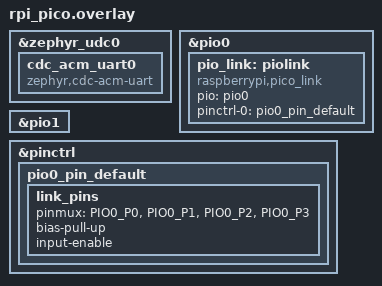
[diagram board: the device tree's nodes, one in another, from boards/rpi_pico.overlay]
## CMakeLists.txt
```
cmake_minimum_required(VERSION 3.20.0)

set(CMAKE_CXX_STANDARD 20)
set(CMAKE_CXX_STANDARD_REQUIRED ON)

# The following resolves the Zephyr location using the ZEPHYR_BASE environment variable.
# The `REQUIRED HINTS $ENV{ZEPHYR_BASE}` is optional in case you're not using `west zephyr-export`
# https://docs.zephyrproject.org/latest/develop/west/zephyr-cmds.html#installing-cmake-packages-west-zephyr-export

# Only set ZEPHYR_MODULES manually if modules are vendored locally.
# When building with west, modules are discovered automatically.
if(EXISTS "${CMAKE_SOURCE_DIR}/modules/hal/rpi_pico")
    set(ZEPHYR_MODULES "${CMAKE_SOURCE_DIR}/modules/hal/rpi_pico" "${CMAKE_SOURCE_DIR}/modules/hal/cmsis")
endif()

set(BOARD rpi_pico)

find_package(Zephyr REQUIRED HINTS "${CMAKE_SOURCE_DIR}/zephyr" $ENV{ZEPHYR_BASE})

project(
    EmptyApp
    VERSION 0.1
    DESCRIPTION "Empty Zephyr application."
    LANGUAGES C
)

# The target "app" is defined in Zephyr's CMake package and is the default target for Zephyr apps.
target_sources(
    app
    PRIVATE
    src/main.cpp
    src/hardware.cpp
    src/persist.cpp
)

set_compiler_property(PROPERTY diagnostic -fdiagnostics-color=never)


add_subdirectory(src/layers)
add_subdirectory(src/payloads)
add_subdirectory(src/sections)
add_subdirectory(src/module)
```

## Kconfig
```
mainmenu "GBLink Device Settings"
source "Kconfig.zephyr"

menu "Application Options"
    config SECTIONS_USE_MASTER_MODE
    bool "Use master mode to connect"
    default y
    help
        Use master mode to connect. 
        Disbale for slave mode to help debug slave setting
        WARNING for future Nils: This will probably not work since Game saves player under player ID which will swap if
        in next section device will switch to master. Why it works in "disconnect" is unkown, but probably due to slightly
        different code paths. To confirm see "DoesLinkPlayerCountMatchSaved" and change accordingly 

    config GB_LINK_MODE_ENABLED
    bool "Enable Game Boy link mode"
    default y
    help
        Enable support for Game Boy link communication.
        This adds the GB SPI passthrough and printer modes.

    config GB_LINK_DRIVE_SD_LOW
    bool "Drive SD pin LOW in GB link mode (generic GBC cable GBA support)"
    default n
    depends on GB_LINK_MODE_ENABLED
    help
        Drive the SD pin (pin 4 of the link connector) LOW whenever GB link
        mode is active.

        OEM GBC link cables leave pin 4 unconnected, so this has no effect
        on them. Generic GBC cables wire all 6 pins through, including pin 4,
        which means the SD signal actually reaches the GBA.

        The GBA reads SIOCNT bit 3 (SD state) to detect whether an external
        clock master is present. With SD floating HIGH (the default when this
        option is off) the GBA may not recognise the adapter as the master,
        causing GBA-mode transfers to fail. Driving SD LOW tells the GBA that
        an external device is driving the clock, which is the correct state
        when the adapter is acting as SPI master.

        Enable this option when using a generic GBC cable to connect to a GBA
        (e.g. for Gen 3 trading or multiboot). Safe to leave enabled even with
        OEM cables or original GB/GBC hardware — those devices either ignore
        the SD pin or treat SD LOW as a valid "external master" signal.

    config GBC_CABLE_ON_GBA
    bool "Use generic GBC cable for GBA mode (SD on GP4)"
    default n
    help
        Enable when using a generic GBC link cable to connect to a GBA.
        Generic GBC cables wire all 6 pins through; on this PCB that routes
        the SD signal to GP4 rather than the standard GP3. Without this
        option SD is read from GP3 (correct for OEM GBA cables).
endmenu
```

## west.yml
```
manifest:
  self:
    path: gblink-firmware

  remotes:
    - name: zephyrproject-rtos
      url-base: https://github.com/zephyrproject-rtos

  projects:
    - name: zephyr
      remote: zephyrproject-rtos
      revision: v4.4-branch
      import:
        name-allowlist:
          - cmsis
          - hal_rpi_pico
```

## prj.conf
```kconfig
CONFIG_GPIO=y
CONFIG_DMA=y
CONFIG_COUNTER=y
CONFIG_EVENTS=y

CONFIG_SPEED_OPTIMIZATIONS=n
CONFIG_DEBUG=y

CONFIG_STDOUT_CONSOLE=y
CONFIG_USB_DEVICE_STACK=y
CONFIG_USB_DEVICE_BOS=y
CONFIG_USB_COMPOSITE_DEVICE=y
CONFIG_USB_CDC_ACM=y
# Composite (vendor + CDC) needs more concurrent transfers than the defaults.
CONFIG_USB_MAX_NUM_TRANSFERS=8
CONFIG_USB_NUMOF_EP_WRITE_RETRIES=10
CONFIG_SERIAL=y
CONFIG_USB_DEVICE_PRODUCT="GBLink USB"
CONFIG_USB_DEVICE_PID=0x000A
CONFIG_UART_INTERRUPT_DRIVEN=y
CONFIG_UART_LINE_CTRL=y
CONFIG_RING_BUFFER=y
CONFIG_USB_DEVICE_INITIALIZE_AT_BOOT=n

CONFIG_CPP=y
CONFIG_STD_CPP20=y
CONFIG_NEWLIB_LIBC=y
CONFIG_NEWLIB_LIBC_NANO=y
CONFIG_REQUIRES_FULL_LIBCPP=y

CONFIG_TICKLESS_KERNEL=y

CONFIG_THREAD_MONITOR=y
CONFIG_THREAD_NAME=y
CONFIG_DEBUG_THREAD_INFO=y
CONFIG_ASSERT=y

CONFIG_PINCTRL=y

# Flash storage for persistent settings (the WebUSB landing-page toggle).
CONFIG_FLASH=y
CONFIG_FLASH_MAP=y
CONFIG_FLASH_PAGE_LAYOUT=y

CONFIG_SECTIONS_USE_MASTER_MODE=y
CONFIG_REBOOT=y
# Driving SD low is opt-in (off by default). For rare compatibility issues with some GBAs.
CONFIG_GB_LINK_DRIVE_SD_LOW=n
```

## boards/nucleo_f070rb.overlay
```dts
#include <zephyr/dt-bindings/pinctrl/stm32-pinctrl.h>

&dma1 { 
    status = "okay";
};

&usb {
    pinctrl-0 = <&usb_dm_pa11 &usb_dp_pa12>;
	pinctrl-names = "default";
    status = "okay";

    cdc_acm_uart0: cdc_acm_uart0 {
        compatible = "zephyr,cdc-acm-uart";
    };
};

&timers16 {
    status = "okay";
    st,prescaler = <0x0F>;
    counter {
        status = "okay";
    };
};

&timers17 {
    status = "okay";
    st,prescaler = <0>;
    counter {
        status = "okay";
    };
};
```

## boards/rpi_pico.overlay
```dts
#include <zephyr/dt-bindings/pinctrl/rpi-pico-rp2040-pinctrl.h>

&zephyr_udc0 {
    cdc_acm_uart0: cdc_acm_uart0 {
        compatible = "zephyr,cdc-acm-uart";
    };
};

&pio0 {
    status = "okay";

    pio_link: piolink {
        compatible = "raspberrypi,pico_link";
        status = "okay";
        pio = <&pio0>;
        pinctrl-0 = <&pio0_pin_default>;
        pinctrl-names = "default";
    };
};

&pio1 {
    status = "okay";
};

&pinctrl {
    pio0_pin_default: pio0_pin_default {
        link_pins {
            pinmux = <PIO0_P0>, <PIO0_P1>, <PIO0_P2>, <PIO0_P3>;
            bias-pull-up;
            input-enable;
        };
    };
};
```

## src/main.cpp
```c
#include <zephyr/kernel.h>

#include "control.hpp"

#include "./layers/packet/packetLayer.hpp"

#include "link_defines.h"

int main(void)
{
    Control g_control = Control();
    while (true)
    {
        g_control.executeMode();
    }
    

    return 0;
}
```

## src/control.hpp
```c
#include "layers/usbLayer.hpp"
#include "layers/serialLayer.hpp"
#include "layers/transport.hpp"
#include "layers/packet/packetLayer.hpp"
#include "module/link.hpp"
#include "module/emu.hpp"
#include "module/gb.hpp"
#include "module/advanceWars.hpp"
#include "module/eReader.hpp"
#include "sections/eReaderProtocolSection.hpp"
#include "linkStatus.hpp"
#include "layers/packet/packetCommands/commands.hpp"
#include "payloads/pokemon.hpp"
#include "module/moduleInterface.hpp"
#include "hardware.hpp"
#include "persist.hpp"
#include "firmware_version.hpp"

class Control
{
    enum class ControlCommand
    {
        SetMode = 0x00,
        Cancel = 0x01,
        EnterGBPrinter = 0x03,
        GetFirmwareInfo = 0x0F
    };

    enum class Mode
    {
        gbaTradeEmu = 0x00,
        gbaLink = 0x01,
        gbLink = 0x02,
        gbPrinter = 0x03,
        advanceWars = 0x04,
        gbaEreader = 0x05,
    };

    static constexpr uint8_t callSetModeId = 0x01;

public:
    Control()
    {
        Transport::registerCommandHandler(receiveCommandHandler, this);

        k_sem_init(&m_waitForModeSemaphore, 0, 1);

        // Persisted cable selection = boot default for the session override.
        cableDetection_setCableOverride(getCableSelection());
    }

    void executeMode()
    {
        k_sem_take(&m_waitForModeSemaphore, K_FOREVER);
        // Capture the requested mode; callSetMode always sets m_mode before
        // giving the semaphore (including when preempting a running mode), so we
        // must not clobber it below. The variant travels with the mode.
        const Mode mode = m_mode;
        const uint8_t modeVariant = m_modeVariant;
        sendLinkStatus(LinkStatus::DeviceReady);

        switch (mode)
        {
            case Mode::gbaTradeEmu:
            {
                applyLedForSlot(LED_SLOT_GBA);
                cableDetection_detectCableType();

                party::partyInit();
                Transport::registerDataHandler(party::usbReceivePkmFile, nullptr);

                EmuModule emuModule;
                m_currentModule = &emuModule;
                emuModule.execute();

                sendLinkStatus(LinkStatus::EmuTradeSessionFinished);
                break;
            }

            case Mode::gbaLink:
            {
                applyLedForSlot(LED_SLOT_GBA);
                cableDetection_detectCableType();

                Transport::registerDataHandler(usbLink_receiveHandler, nullptr);

                LinkModule linkModule;
                m_currentModule = &linkModule;
                linkModule.execute();

                sendLinkStatus(LinkStatus::LinkClosed);
                break;
            }

            case Mode::gbLink:
            {
                GBModule gbModule;
                m_currentModule = &gbModule;
                gbModule.execute();  // Sets blue LED internally

                sendLinkStatus(LinkStatus::GBSessionFinished);
                break;
            }

            case Mode::gbPrinter:
            {
                GBModule gbModule;
                m_currentModule = &gbModule;
                gbModule.executePrinterMode();  // Sets purple LED internally

                sendLinkStatus(LinkStatus::GBSessionFinished);
                break;
            }

            case Mode::advanceWars:
            {
                applyLedForSlot(LED_SLOT_ADVANCE_WARS);
                cableDetection_detectCableType();

                Transport::registerDataHandler(awProto_receiveHandler, nullptr);

                AdvanceWarsModule advanceWarsModule(
                    modeVariant == 2 ? awproto::GameVariant::aw2
                                     : awproto::GameVariant::aw1);
                m_currentModule = &advanceWarsModule;
                advanceWarsModule.execute();

                sendLinkStatus(LinkStatus::LinkClosed);
                break;
            }

            case Mode::gbaEreader:
            {
                applyLedForSlot(LED_SLOT_EREADER);
                cableDetection_detectCableType();

                Transport::registerDataHandler(erProto_receiveHandler, nullptr);

                const erproto::Profile profile =
                    modeVariant == 2 ? erproto::Profile::pokemonRuby :
                    modeVariant == 3 ? erproto::Profile::sma4JPN :
                    modeVariant == 4 ? erproto::Profile::pokemonRubyJPN :
                    modeVariant == 5 ? erproto::Profile::sma4EUR :
                    modeVariant == 6 ? erproto::Profile::sma4EURFra :
                    modeVariant == 7 ? erproto::Profile::sma4EURGer :
                    modeVariant == 8 ? erproto::Profile::sma4EUREsp :
                    modeVariant == 9 ? erproto::Profile::sma4EURIta
                                   : erproto::Profile::sma4;
                EReaderModule ereaderModule(profile);
                m_currentModule = &ereaderModule;
                ereaderModule.execute();

                sendLinkStatus(LinkStatus::LinkClosed);
                break;
            }
        }

        m_currentModule = nullptr;
        applyLedForSlot(LED_SLOT_IDLE); // green = connected, no active mode
    }

private:
    struct k_sem m_waitForModeSemaphore;
    Mode m_mode;
    uint8_t m_modeVariant = 0;

    IModule* m_currentModule = nullptr;

    bool canHandle(uint8_t command) { return (command & 0xF0) == 0x00; }

    // Hardware commands (0x40-0x4F) are device-level, handled regardless of active module
    bool isHardwareCommand(uint8_t command) { return (command & 0xF0) == 0x40; }

    enum class HardwareCommand : uint8_t
    {
        SetVoltage3V3 = 0x40,
        SetVoltage5V = 0x41,
        SetLEDColor = 0x42,
        RebootBootloader = 0x43,
        SetWebUsbLanding = 0x44,
        GetLedConfig = 0x45,
        SetModeLedColor = 0x46,
        ResetLedColors = 0x47,
        Reboot = 0x48,
        SetCableOverride = 0x49,
        GetCableType = 0x4a,
        SetCableSelection = 0x4b,
    };

    void receiveCommand(std::span<const uint8_t> data)
    {
        if (data.empty()) return;

        // Handle hardware commands first (device-level, always available)
        if (isHardwareCommand(data[0]))
        {
            return handleHardwareCommand(data);
        }

        if (m_currentModule != nullptr && m_currentModule->canHandle(data[0]))
        {
            return m_currentModule->receiveCommand(data);
        } 
        
        if (!canHandle(data[0])) return;
        switch (static_cast<ControlCommand>(data[0]))
        {
            // Optional third byte selects a game variant within the mode
            // (Advance Wars: 1 = AW1, 2 = AW2; e-reader: 1 = SMA4 US,
            // 2 = Pokemon RS US, 3 = SMA4 JPN, 4 = Pokemon RS JPN,
            // 5-9 = SMA4 EUR En/Fr/De/Es/It; defaults to the first variant
            // for older clients that send only [command, mode]).
            case ControlCommand::SetMode:
                if (data.size() < 2) return;
                return callSetMode(static_cast<Mode>(data[1]),
                                   data.size() >= 3 ? data[2] : 0);
            case ControlCommand::Cancel: return callCancel();
            case ControlCommand::EnterGBPrinter: return callSetMode(Mode::gbPrinter);
            case ControlCommand::GetFirmwareInfo: return callGetFirmwareInfo();
            default: return;
        }
    }

    void handleHardwareCommand(std::span<const uint8_t> data)
    {
        switch (static_cast<HardwareCommand>(data[0]))
        {
            case HardwareCommand::SetVoltage3V3:
                Hardware::getInstance().setVoltage3V3();
                break;
            case HardwareCommand::SetVoltage5V:
                Hardware::getInstance().setVoltage5V();
                break;
            case HardwareCommand::SetLEDColor:
                if (data.size() >= 5) {
                    Hardware::getInstance().setLED(data[1], data[2], data[3], data[4] != 0);
                }
                break;
            case HardwareCommand::RebootBootloader:
                // Resets into the USB bootloader; does not return.
                Hardware::getInstance().rebootToBootloader();
                break;
            case HardwareCommand::SetWebUsbLanding:
                // Persist the WebUSB landing-page toggle; applies on next reconnect.
                if (data.size() >= 2) {
                    setLandingPageEnabled(data[1] != 0);
                }
                break;
            case HardwareCommand::GetLedConfig:
                return callGetLedConfig();
            case HardwareCommand::SetModeLedColor:
                // [0x46, slot, r, g, b] — persist a mode's LED colour.
                if (data.size() >= 5) {
                    setLedColor(data[1], data[2], data[3], data[4]);
                }
                break;
            case HardwareCommand::ResetLedColors:
                // Restore all per-mode LED colours to the built-in defaults.
                resetLedColors();
                break;
            case HardwareCommand::Reboot:
                // Warm-reboot into the app so persisted settings apply now; no return.
                Hardware::getInstance().reboot();
                break;
            case HardwareCommand::SetCableOverride:
                if (data.size() >= 2) {
                    cableDetection_setCableOverride(data[1]);
                }
                break;
            case HardwareCommand::GetCableType:
            {
                // Report-only: the cable is sampled once at mode entry (a GBA
                // already in link mode drives SO low, which would poison a
                // re-sample); the override command changes the path instead.
                uint8_t resp[2] = { 0x4a, static_cast<uint8_t>(cableDetection_getDetectedCableType()) };
                Transport::sendData(std::span<const uint8_t>(resp, sizeof(resp)));
                break;
            }
            case HardwareCommand::SetCableSelection:
                // [0x4b, CABLE_*] — persist the cable selection and apply it now.
                if (data.size() >= 2 && data[1] <= CABLE_FORCE_GBC) {
                    setCableSelection(data[1]);
                    cableDetection_setCableOverride(data[1]);
                }
                break;
            default: break;
        }
    }

    void callGetLedConfig()
    {
        // [0x45, count, r0,g0,b0, ... r5,g5,b5]
        uint8_t info[2 + LED_SLOT_COUNT * 3];
        info[0] = static_cast<uint8_t>(HardwareCommand::GetLedConfig);
        info[1] = LED_SLOT_COUNT;
        for (uint8_t slot = 0; slot < LED_SLOT_COUNT; slot++) {
            getLedColor(slot, &info[2 + slot * 3]);
        }
        Transport::sendData(std::span<const uint8_t>(info, sizeof(info)));
    }

    //-////////////////////////////////////////////////////////////////////////////////////////////////////////-//
    // CALLS
    //-////////////////////////////////////////////////////////////////////////////////////////////////////////-//

    void callSetMode(Mode mode, uint8_t variant = 0)
    {
        m_mode = mode;
        m_modeVariant = variant;
        // If a mode is already running, cancel it so executeMode unblocks and
        // switches to the new mode (otherwise SetMode would queue behind a mode
        // that never exits). Same cancel path the web "cancel" command uses.
        if (m_currentModule != nullptr)
        {
            m_currentModule->cancel();
        }
        k_sem_give(&m_waitForModeSemaphore);
    }

    void callCancel()
    {
        if (m_currentModule != nullptr) m_currentModule->cancel();
    }

    void callGetFirmwareInfo()
    {
        const uint8_t info[] = {
            0x0F, // Echo back the command ID so web app knows this is a firmware info response
            fw::versionMajor,
            fw::versionMinor,
            fw::versionPatch,
            // Byte 4: WebUSB landing-page enabled (1) / disabled (0). Older web
            // apps simply ignore the extra byte.
            static_cast<uint8_t>(landingPageEnabled() ? 1 : 0),
            // Byte 5: persisted cable selection (CABLE_*).
            getCableSelection()
        };
        Transport::sendData(std::span<const uint8_t>(info, sizeof(info)));
    }

    //-////////////////////////////////////////////////////////////////////////////////////////////////////////-//

    static void receiveCommandHandler(std::span<const uint8_t> receivedData, void* userData)
    {
        Control* self = static_cast<Control*>(userData);
        self->receiveCommand(receivedData);
    }
};
```

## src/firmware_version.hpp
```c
#pragma once

#include <cstdint>

// Single source for the firmware version. It is reported over the
// protocol (GetFirmwareInfo) and folded into the USB bcdDevice (see usbLayer.cpp).
//
// Why bcdDevice tracks the version: Windows caches a device's MS OS / WinUSB
// driver binding keyed by VID/PID/bcdDevice. If bcdDevice never changes, a host
// that cached an older descriptor keeps the stale binding after a firmware
// update and will not re-read the corrected descriptors. Advancing bcdDevice on
// every release makes Windows treat it as a new device and re-enumerate cleanly.
namespace fw
{
    inline constexpr uint8_t versionMajor = 2;
    inline constexpr uint8_t versionMinor = 2;
    inline constexpr uint8_t versionPatch = 1;

    // Packed BCD nibbles 0x0<major><minor><patch>, e.g. 2.2.1 -> 0x0221.
    // Keep each field <= 9 to stay valid BCD.
    inline constexpr uint16_t bcdDevice =
        (static_cast<uint16_t>(versionMajor) << 8) |
        (static_cast<uint16_t>(versionMinor) << 4) |
        static_cast<uint16_t>(versionPatch);
}
```

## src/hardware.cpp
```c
#include "hardware.hpp"

#include <zephyr/kernel.h>
#include "hardware/pio.h"
#include "hardware/gpio.h"
#include "hardware/clocks.h"
#include "hardware/timer.h"

extern "C" {
#include <zephyr/drivers/misc/pio_rpi_pico/pio_rpi_pico.h>
}

// --- Pin Definitions ---
#define WS2812_PIN      16
#define VSWITCH_3V3_PIN 11
#define VSWITCH_5V_PIN  12

// --- WS2812 PIO Program (4 instructions) ---
// Ported from gb-link-firmware-reconfigurable/main.c
static const uint16_t ws2812_program_instructions[] = {
    0x6221, //  0: out    x, 1       side 0 [2]
    0x1123, //  1: jmp    !x, 3      side 1 [1]
    0x1400, //  2: jmp    0          side 1 [4]
    0xa442, //  3: nop               side 0 [4]
};

static const struct pio_program ws2812_program = {
    .instructions = ws2812_program_instructions,
    .length = 4,
    .origin = -1,
};

// WS2812 uses pio1 (independent from link SPI on pio0)
static PIO g_ws2812_pio = NULL;
static uint g_ws2812_sm = 0;
static bool g_ws2812_initialized = false;

// --- Hardware Singleton ---

Hardware& Hardware::getInstance()
{
    static Hardware instance;
    return instance;
}

Hardware::Hardware()
{
    // Initialize voltage switching GPIOs (raw Pico SDK, matching linkLayer_pio.c pattern)
    gpio_init(VSWITCH_3V3_PIN);
    gpio_init(VSWITCH_5V_PIN);
    gpio_set_dir(VSWITCH_3V3_PIN, GPIO_OUT);
    gpio_set_dir(VSWITCH_5V_PIN, GPIO_OUT);

    // Safe state: both HIGH first
    gpio_put(VSWITCH_3V3_PIN, 1);
    gpio_put(VSWITCH_5V_PIN, 1);
    busy_wait_us(100);

    // Default to 3.3V mode
    gpio_put(VSWITCH_3V3_PIN, 0);

    // Initialize WS2812 NeoPixel
    ws2812Init();

    // Set initial LED to red (disconnected state)
    ws2812Set(0x000500); // GRB format: G=0x00, R=0x05, B=0x00
}

void Hardware::ws2812Init()
{
    // Pico SDK defines 'pio1' as a macro (pio1_hw) which breaks DT_NODELABEL.
    // Temporarily undefine it so device tree lookup works.
    #undef pio1
    const struct device* dev = DEVICE_DT_GET(DT_NODELABEL(pio1));
    if (!device_is_ready(dev)) {
        return;
    }

    g_ws2812_pio = pio_rpi_pico_get_pio(dev);
    pio_rpi_pico_allocate_sm(dev, &g_ws2812_sm);

    uint offset = pio_add_program(g_ws2812_pio, &ws2812_program);

    // Configure state machine for WS2812 protocol
    pio_gpio_init(g_ws2812_pio, WS2812_PIN);
    pio_sm_set_consecutive_pindirs(g_ws2812_pio, g_ws2812_sm, WS2812_PIN, 1, true);

    pio_sm_config c = pio_get_default_sm_config();
    sm_config_set_sideset(&c, 1, false, false);
    sm_config_set_sideset_pins(&c, WS2812_PIN);
    sm_config_set_out_shift(&c, false, true, 24);
    sm_config_set_fifo_join(&c, PIO_FIFO_JOIN_TX);
    sm_config_set_wrap(&c, offset, offset + 3);
    sm_config_set_clkdiv(&c, clock_get_hz(clk_sys) / (800000.0f * 8.0f));

    pio_sm_init(g_ws2812_pio, g_ws2812_sm, offset, &c);
    pio_sm_set_enabled(g_ws2812_pio, g_ws2812_sm, true);

    g_ws2812_initialized = true;
}

void Hardware::ws2812Set(uint32_t grb)
{
    if (!g_ws2812_initialized) return;
    pio_sm_put_blocking(g_ws2812_pio, g_ws2812_sm, grb << 8u);
}

// --- Public API ---

void Hardware::setVoltage3V3()
{
    // Both HIGH first (safe off), then pull 3.3V LOW
    gpio_put(VSWITCH_3V3_PIN, 1);
    gpio_put(VSWITCH_5V_PIN, 1);
    busy_wait_us(100);
    gpio_put(VSWITCH_3V3_PIN, 0);
}

void Hardware::setVoltage5V()
{
    // Both HIGH first (safe off), then pull 5V LOW
    gpio_put(VSWITCH_3V3_PIN, 1);
    gpio_put(VSWITCH_5V_PIN, 1);
    busy_wait_us(100);
    gpio_put(VSWITCH_5V_PIN, 0);
}

void Hardware::setLED(uint8_t r, uint8_t g, uint8_t b, bool on)
{
    if (on) {
        // NeoPixel expects GRB format
        uint32_t grb = ((uint32_t)g << 16) | ((uint32_t)r << 8) | b;
        ws2812Set(grb);
    } else {
        ws2812Set(0x000000);
    }
}

// --- Boot-time Initialization ---
static int hardware_init()
{
    Hardware::getInstance();
    return 0;
}

SYS_INIT(hardware_init, APPLICATION, 0);
```

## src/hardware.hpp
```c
#pragma once

#include <cstdint>

class Hardware {
public:
    static Hardware& getInstance();

    Hardware(const Hardware&) = delete;
    Hardware& operator=(const Hardware&) = delete;
    Hardware(Hardware&&) = delete;
    Hardware& operator=(Hardware&&) = delete;

    void setVoltage3V3();
    void setVoltage5V();
    void setLED(uint8_t r, uint8_t g, uint8_t b, bool on);

private:
    Hardware();
    void ws2812Init();
    void ws2812Set(uint32_t grb);
};
```

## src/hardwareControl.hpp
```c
#include "layers/transport/transportLayer.hpp"
#include "module/link.hpp"
#include "module/emu.hpp"
#include "module/advanceWars.hpp"
#include "callbacks/commands.hpp"
#include "hardware.hpp"
#include "persist.hpp"
#include <cstdint>

#pragma once

// Hardware commands (0x40-0x4F) are device-level, handled regardless of active module

    enum class HardwareCommand : uint8_t
    {
        SetVoltage = 0x40,
        SetLEDColor = 0x42,
        RebootBootloader = 0x43,
        SetWebUsbLanding = 0x44,
        GetLedConfig = 0x45,
        SetModeLedColor = 0x46,
        ResetLedColors = 0x47,
        Reboot = 0x48,
    };

class HardwareControl 
{
public:
    bool canHandle(uint8_t command) { return (command & 0xF0) == 0x40; }
    
    void handleCall(Call& call)
    {
        switch (static_cast<HardwareCommand>(call.fid))
        {
            case HardwareCommand::SetVoltage: return callSetVoltage(call);
            case HardwareCommand::SetLEDColor: return callSetLedColor(call);
            case HardwareCommand::RebootBootloader: return callReboot(call);
            case HardwareCommand::GetLedConfig: return callGetLedConfig(call);
            case HardwareCommand::SetModeLedColor: return callSetModeLedColor(call);
            case HardwareCommand::SetWebUsbLanding: return callSetWebUsbLanding(call);
            case HardwareCommand::ResetLedColors: return callResetColors(call);
            default: break;
        }
    }

private:
    void callGetLedConfig(Call& call)
    {
        // [0x45, count, r0,g0,b0, ... r4,g4,b4]
        uint8_t info[2 + LED_SLOT_COUNT * 3];
        info[0] = static_cast<uint8_t>(HardwareCommand::GetLedConfig);
        info[1] = LED_SLOT_COUNT;
        for (uint8_t slot = 0; slot < LED_SLOT_COUNT; slot++) {
            getLedColor(slot, &info[2 + slot * 3]);
        }
    }

    void callSetVoltage(Call& call)
    {
        switch(call.params()[0])
        {
            case 0x00: Hardware::getInstance().setVoltage3V3(); break;
            case 0x01: Hardware::getInstance().setVoltage5V(); break;
        };
    }

    void callSetLedColor(Call& call)
    {
        if (call.params().size() >= 4) 
        {
            Hardware::getInstance().setLED(
                call.params()[0], 
                call.params()[1], 
                call.params()[2], 
                call.params()[3] != 0
            );
        }
        break;
    }

    void callReboot(Call& call)
    {
        switch(call.params()[0])
        {
            case 0x00: Hardware::getInstance().rebootToBootloader(); break;
            case 0x01: Hardware::getInstance().reboot(); break;
        }
    }

    void callSetModeLedColor(Call& call)
    {
        if (call.params().size() >= 4) 
        {
            Hardware::getInstance().setLedColor(
                call.params()[0], 
                call.params()[1], 
                call.params()[2], 
                call.params()[3] != 0
            );
        }
        break;
    }

    void callSetWebUsbLanding(Call& call)
    {
        if (call.params().size() >= 1) 
        {
            setLandingPageEnabled(data[0] != 0);
        }
    }

    void callResetColors(Call& call)
    {
        resetLedColors();
    }
};
```

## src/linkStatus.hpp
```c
#include <zephyr/kernel.h>
#include "./layers/transport/transport.hpp"

#pragma once

enum class LinkStatus : uint16_t
{
    GameboyConnected = 0xFF00,
    GameboyDisconnected = 0xFF01,

    AwaitMode = 0xFF02,
    HandshakeReceived = 0xFF03,
    HandshakeFinished = 0xFF04,

    LinkConnected = 0xFF05,
    LinkReconnecting = 0xFF06,
    LinkClosed = 0xFF07,

    DeviceReady = 0xFF08,
    EmuTradeSessionFinished = 0xFF09,

    GBModeActive = 0xFF0A,
    GBPrinterModeActive = 0xFF0B,
    GBSessionFinished = 0xFF0C,

    StatusDebug = 0xFFFF
};

inline bool sendLinkStatus(LinkStatus status)
{
    return Transport::sendStatus(std::span<const uint8_t, 2>(reinterpret_cast<const uint8_t*>(&status), 2));
}
```

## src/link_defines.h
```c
#define LINKCMD_BLENDER_STOP            0x1111
#define LINKCMD_SEND_LINK_TYPE          0x2222
#define LINKCMD_BLENDER_SCORE_MISS      0x2345
#define LINKCMD_READY_EXIT_STANDBY      0x2FFE
#define LINKCMD_SEND_PACKET             0x2FFF
#define LINKCMD_BLENDER_SEND_KEYS       0x4444
#define LINKCMD_BLENDER_SCORE_BEST      0x4523
#define LINKCMD_BLENDER_SCORE_GOOD      0x5432
#define LINKCMD_DUMMY_1                 0x5555
#define LINKCMD_DUMMY_2                 0x5566
#define LINKCMD_READY_CLOSE_LINK        0x5FFF
#define LINKCMD_SEND_EMPTY              0x6666
#define LINKCMD_SEND_0xEE               0x7777
#define LINKCMD_BLENDER_PLAY_AGAIN      0x7779
#define LINKCMD_COUNTDOWN               0x7FFF
#define LINKCMD_CONT_BLOCK              0x8888
#define LINKCMD_BLENDER_NO_BERRIES      0x9999
#define LINKCMD_BLENDER_NO_PBLOCK_SPACE 0xAAAA
#define LINKCMD_SEND_ITEM               0xAAAB
#define LINKCMD_READY_TO_TRADE          0xAABB
#define LINKCMD_READY_FINISH_TRADE      0xABCD
#define LINKCMD_INIT_BLOCK              0xBBBB
#define LINKCMD_READY_CANCEL_TRADE      0xBBCC
#define LINKCMD_SEND_HELD_KEYS          0xCAFE
#define LINKCMD_SEND_BLOCK_REQ          0xCCCC
#define LINKCMD_START_TRADE             0xCCDD
#define LINKCMD_CONFIRM_FINISH_TRADE    0xDCBA
#define LINKCMD_SET_MONS_TO_TRADE       0xDDDD
#define LINKCMD_PLAYER_CANCEL_TRADE     0xDDEE
#define LINKCMD_REQUEST_CANCEL          0xEEAA
#define LINKCMD_BOTH_CANCEL_TRADE       0xEEBB
#define LINKCMD_PARTNER_CANCEL_TRADE    0xEECC
#define LINKCMD_NONE                    0xEFFF

#define LINKCMD_EMPTY                   0x0000

#define LINKTYPE_TRADE               0x1111
#define LINKTYPE_TRADE_CONNECTING    0x1122
#define LINKTYPE_TRADE_SETUP         0x1133
#define LINKTYPE_TRADE_DISCONNECTED  0x1144
#define LINKTYPE_BATTLE              0x2211
#define LINKTYPE_UNUSED_BATTLE       0x2222 // Unused, inferred from gap
#define LINKTYPE_SINGLE_BATTLE       0x2233
#define LINKTYPE_DOUBLE_BATTLE       0x2244
#define LINKTYPE_MULTI_BATTLE        0x2255
#define LINKTYPE_BATTLE_TOWER_50     0x2266
#define LINKTYPE_BATTLE_TOWER_OPEN   0x2277
#define LINKTYPE_BATTLE_TOWER        0x2288
#define LINKTYPE_RECORD_MIX_BEFORE   0x3311
#define LINKTYPE_RECORD_MIX_AFTER    0x3322
#define LINKTYPE_BERRY_BLENDER_SETUP 0x4411
#define LINKTYPE_BERRY_BLENDER       0x4422
#define LINKTYPE_MYSTERY_EVENT       0x5501
#define LINKTYPE_EREADER_FRLG        0x5502
#define LINKTYPE_EREADER_EM          0x5503
#define LINKTYPE_CONTEST_GMODE       0x6601
#define LINKTYPE_CONTEST_EMODE       0x6602

#define LINK_PLAYER_ID              0x81

#define LINK_MASTER_HANDSHAKE       0x8FFF
#define LINK_SLAVE_HANDSHAKE        0xB9A0
#define LINK_HANDSHAKE_DISABLE      0xD15E

#define LINK_KEY_CODE_NULL 0x00
#define LINK_KEY_CODE_EMPTY 0x11
#define LINK_KEY_CODE_DPAD_DOWN 0x12
#define LINK_KEY_CODE_DPAD_UP 0x13
#define LINK_KEY_CODE_DPAD_LEFT 0x14
#define LINK_KEY_CODE_DPAD_RIGHT 0x15
#define LINK_KEY_CODE_READY 0x16
#define LINK_KEY_CODE_EXIT_ROOM 0x17
#define LINK_KEY_CODE_START_BUTTON 0x18
#define LINK_KEY_CODE_A_BUTTON 0x19
#define LINK_KEY_CODE_IDLE 0x1A
```

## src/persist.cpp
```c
#include "persist.hpp"
#include "hardware.hpp"
#include "layers/link/cableDetection/cableDetection.hpp" // CABLE_* selection values


#include <cstring>
#include <zephyr/storage/flash_map.h>

namespace
{
    #define STORAGE_PARTITION_ID FIXED_PARTITION_ID(storage_partition)

    constexpr uint8_t SETTINGS_MAGIC = 0x5A;
    constexpr uint8_t SETTINGS_VERSION = 7; // bumped for the cable selection

    struct PersistSettings
    {
        uint8_t magic;
        uint8_t version;
        uint8_t landing;                       // 0 = disabled, else enabled
        uint8_t led[LED_SLOT_COUNT][3];        // per-slot logical RGB
        uint8_t cable;                         // CABLE_* SD-pin selection
    };

    // Real-colour defaults at a uniform 12.5% brightness (32/255) so every mode's
    // brightness slider starts at the same place. WS2812 magnitude = brightness.
    const uint8_t kDefaultColors[LED_SLOT_COUNT][3] = {
        { 0,   32,  0   }, // idle/connected — green
        { 32,  32,  0   }, // GBA/Celio — yellow
        { 0,   0,   32  }, // GB/GBC — blue
        { 32,  0,   32  }, // printer — purple
        { 32,  32,  32  }, // Advance Wars — white
        { 0,   10,  32  }, // e-reader — light blue
    };

    void fillDefaults(PersistSettings& s)
    {
        s.magic = SETTINGS_MAGIC;
        s.version = SETTINGS_VERSION;
        s.landing = 1;
        memcpy(s.led, kDefaultColors, sizeof(s.led));
        s.cable = CABLE_FORCE_GBC;
    }

    // Defaults when flash is unwritten; older layouts migrate in place (written
    // back on the next save). Pre-v7 loads cable = auto-detect so an updated
    // adapter keeps its pre-selection behavior.
    PersistSettings loadSettings()
    {
        PersistSettings s{};
        const struct flash_area *fa;
        if (flash_area_open(STORAGE_PARTITION_ID, &fa) != 0) {
            fillDefaults(s);
            return s;
        }
        flash_area_read(fa, 0, &s, sizeof(s));
        flash_area_close(fa);

        if (s.magic != SETTINGS_MAGIC) {
            fillDefaults(s);
        } else if (s.version == 6) {
            // v6 = v7 minus the cable byte — keep the user's values. Literal 7:
            s.version = 7;
            s.cable = CABLE_AUTO;
        } else if (s.version != SETTINGS_VERSION) {
            fillDefaults(s);
            s.cable = CABLE_AUTO;
        }
        if (s.cable > CABLE_FORCE_GBC) s.cable = CABLE_FORCE_GBC;
        return s;
    }

    void saveSettings(const PersistSettings& s)
    {
        const struct flash_area *fa;
        if (flash_area_open(STORAGE_PARTITION_ID, &fa) != 0) {
            return;
        }
        // Flash must be erased before writing; RP2040 write-block-size is 1.
        flash_area_erase(fa, 0, fa->fa_size);
        flash_area_write(fa, 0, &s, sizeof(s));
        flash_area_close(fa);
    }
}

bool landingPageEnabled()
{
    return loadSettings().landing != 0;
}

void setLandingPageEnabled(bool enabled)
{
    PersistSettings s = loadSettings();
    s.landing = enabled ? 1 : 0;
    saveSettings(s);
}

uint8_t getCableSelection()
{
    return loadSettings().cable;
}

void setCableSelection(uint8_t cable)
{
    if (cable > CABLE_FORCE_GBC) return;
    PersistSettings s = loadSettings();
    if (s.cable == cable) return; // skip the sector erase on a no-op
    s.cable = cable;
    saveSettings(s);
}

void getLedColor(uint8_t slot, uint8_t out[3])
{
    if (slot >= LED_SLOT_COUNT) { out[0] = out[1] = out[2] = 0; return; }
    PersistSettings s = loadSettings();
    out[0] = s.led[slot][0];
    out[1] = s.led[slot][1];
    out[2] = s.led[slot][2];
}

void setLedColor(uint8_t slot, uint8_t r, uint8_t g, uint8_t b)
{
    if (slot >= LED_SLOT_COUNT) return;
    PersistSettings s = loadSettings();
    s.led[slot][0] = r;
    s.led[slot][1] = g;
    s.led[slot][2] = b;
    saveSettings(s);
}

void resetLedColors()
{
    PersistSettings s = loadSettings();
    memcpy(s.led, kDefaultColors, sizeof(s.led));
    saveSettings(s);
}

void applyLedForSlot(uint8_t slot)
{
    uint8_t c[3];
    getLedColor(slot, c);
    Hardware::getInstance().setLED(c[0], c[1], c[2], true);
}
```

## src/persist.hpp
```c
#pragma once

#include <cstdint>

// Persistent device settings, stored in the dedicated 4 KB flash "storage"
// partition (see boards/rpi_pico.overlay). One versioned struct holds the
// WebUSB landing-page flag and the per-mode LED colors.

// Per-mode LED colour slots (fixed order — shared with the launcher UI).
enum LedSlot : uint8_t {
    LED_SLOT_IDLE = 0,        // connected, no active mode (green)
    LED_SLOT_GBA = 1,         // GBA trade/link (yellow)
    LED_SLOT_GBC = 2,         // GB/GBC link (blue)
    LED_SLOT_PRINTER = 3,     // GB printer (purple)
    LED_SLOT_ADVANCE_WARS = 4,// Advance Wars (white)
    LED_SLOT_COUNT = 5,
};

// WebUSB landing-page advertising. Default (unwritten flash) is enabled.
bool landingPageEnabled();
void setLandingPageEnabled(bool enabled);

// Per-mode LED colours (logical RGB, 0-255; the WS2812 driver does GRB packing).
void getLedColor(uint8_t slot, uint8_t out[3]);
void setLedColor(uint8_t slot, uint8_t r, uint8_t g, uint8_t b);
void resetLedColors(); // restore all slots to the built-in defaults

// Apply a slot's stored colour to the LED now (used at mode entry).
void applyLedForSlot(uint8_t slot);
```
